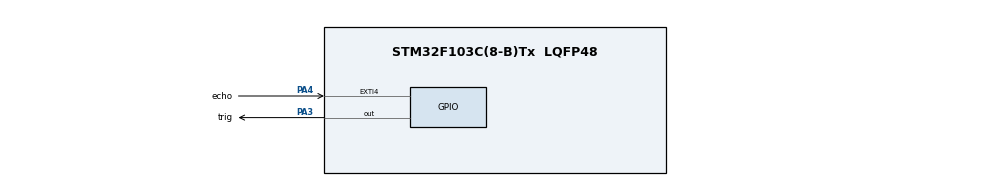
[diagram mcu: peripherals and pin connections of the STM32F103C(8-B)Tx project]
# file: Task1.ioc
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Mcu.Family=STM32F1
Mcu.Name=STM32F103C(8-B)Tx
Mcu.Package=LQFP48
NVIC.EXTI4_IRQn=true\:0\:0\:false\:false\:true\:true\:true\:true
NVIC.PriorityGroup=NVIC_PRIORITYGROUP_4
PA3.GPIO_Label=trig
PA3.Signal=GPIO_Output
PA4.GPIO_Label=echo
PA4.GPIO_ModeDefaultEXTI=GPIO_MODE_IT_RISING_FALLING
PA4.Signal=GPXTI4
ProjectManager.HeapSize=0x200
ProjectManager.StackSize=0x400
ProjectManager.TargetToolchain=STM32CubeIDE
RCC.APB1Freq_Value=8000000
RCC.APB2Freq_Value=8000000
VP_SYS_VS_ND.Mode=No_Debug
VP_TIM1_VS_ClockSourceINT.Mode=Internal
board=custom

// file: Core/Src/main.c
/* USER CODE BEGIN Header */
/**
  ******************************************************************************
  * @file           : main.c
  * @brief          : Main program body
  ******************************************************************************
  * @attention
  *
  * Copyright (c) 2026 STMicroelectronics.
  * All rights reserved.
  *
  * This software is licensed under terms that can be found in the LICENSE file
  * in the root directory of this software component.
  * If no LICENSE file comes with this software, it is provided AS-IS.
  *
  ******************************************************************************
  */
/* USER CODE END Header */
#include "main.h"

TIM_HandleTypeDef htim1;

void SystemClock_Config(void);
static void MX_GPIO_Init(void);
static void MX_TIM1_Init(void);
/* USER CODE BEGIN PFP */
void delay_us(uint16_t us);
/* USER CODE END PFP */

int main(void)
{

  /* MCU Configuration--------------------------------------------------------*/

  /* Reset of all peripherals, Initializes the Flash interface and the Systick. */
  HAL_Init();

  /* Configure the system clock */
  SystemClock_Config();

  /* Initialize all configured peripherals */
  MX_GPIO_Init();
  MX_TIM1_Init();
  /* USER CODE BEGIN 2 */
  HAL_TIM_Base_Start(&htim1);
  LCD_8 l = {
 		  .EN  = { .port = GPIOA, .pin = GPIO_PIN_0 },
 		  .RS  = { .port = GPIOA, .pin = GPIO_PIN_1 },
 		  .RW  = { .port = GPIOA, .pin = GPIO_PIN_2 },
 		  .DB7 = { .port = GPIOB, .pin = GPIO_PIN_7 },
 		  .DB6 = { .port = GPIOB, .pin = GPIO_PIN_6 },
 		  .DB5 = { .port = GPIOB, .pin = GPIO_PIN_5 },
 		  .DB4 = { .port = GPIOB, .pin = GPIO_PIN_4 },
 		  .DB3 = { .port = GPIOB, .pin = GPIO_PIN_3 },
 		  .DB2 = { .port = GPIOB, .pin = GPIO_PIN_2 },
 		  .DB1 = { .port = GPIOB, .pin = GPIO_PIN_1 },
 		  .DB0 = { .port = GPIOB, .pin = GPIO_PIN_0 }
   };
   vidLCDInit(l);
   vidLCDScreenClr(l);
   vidLCDSetCursor(l, R2, C1);
   uint8_t str[16] = "start";
   vidLCDWriteStr(l, str);

   US ultra = {
		   .trig = {
			   .port = GPIOA,
			   .pin = GPIO_PIN_3,
		   },
		   .echo = {
			   .port = GPIOA,
			   .pin = GPIO_PIN_4,

		   },
		   .mode = CM
   };
   uint16_t distance = 5;
   US_read(ultra, &distance);
  /* USER CODE END 2 */

  /* Infinite loop */
  /* USER CODE BEGIN WHILE */
  while (1)
  {

	   US_read(ultra, &distance);
	  sprintf(str, "dist:%d",distance);
	   vidLCDScreenClr(l);
	   vidLCDSetCursor(l, R1, C1);
	   vidLCDWriteStr(l, str);
	  HAL_Delay(100);
    /* USER CODE END WHILE */

  }
}

void SystemClock_Config(void)
{
  RCC_OscInitTypeDef RCC_OscInitStruct = {0};
  RCC_ClkInitTypeDef RCC_ClkInitStruct = {0};

  /** Initializes the RCC Oscillators according to the specified parameters
  * in the RCC_OscInitTypeDef structure.
  */
  RCC_OscInitStruct.OscillatorType = RCC_OSCILLATORTYPE_HSI;
  RCC_OscInitStruct.HSIState = RCC_HSI_ON;
  RCC_OscInitStruct.HSICalibrationValue = RCC_HSICALIBRATION_DEFAULT;
  RCC_OscInitStruct.PLL.PLLState = RCC_PLL_NONE;
  if (HAL_RCC_OscConfig(&RCC_OscInitStruct) != HAL_OK)
  {
    Error_Handler();
  }

  /** Initializes the CPU, AHB and APB buses clocks
  */
  RCC_ClkInitStruct.ClockType = RCC_CLOCKTYPE_HCLK|RCC_CLOCKTYPE_SYSCLK
                              |RCC_CLOCKTYPE_PCLK1|RCC_CLOCKTYPE_PCLK2;
  RCC_ClkInitStruct.SYSCLKSource = RCC_SYSCLKSOURCE_HSI;
  RCC_ClkInitStruct.AHBCLKDivider = RCC_SYSCLK_DIV1;
  RCC_ClkInitStruct.APB1CLKDivider = RCC_HCLK_DIV1;
  RCC_ClkInitStruct.APB2CLKDivider = RCC_HCLK_DIV1;

  if (HAL_RCC_ClockConfig(&RCC_ClkInitStruct, FLASH_LATENCY_0) != HAL_OK)
  {
    Error_Handler();
  }
}

static void MX_TIM1_Init(void)
{

  TIM_ClockConfigTypeDef sClockSourceConfig = {0};
  TIM_MasterConfigTypeDef sMasterConfig = {0};

  htim1.Instance = TIM1;
  htim1.Init.Prescaler = 0;
  htim1.Init.CounterMode = TIM_COUNTERMODE_UP;
  htim1.Init.Period = 65535;
  htim1.Init.ClockDivision = TIM_CLOCKDIVISION_DIV1;
  htim1.Init.RepetitionCounter = 0;
  htim1.Init.AutoReloadPreload = TIM_AUTORELOAD_PRELOAD_DISABLE;
  if (HAL_TIM_Base_Init(&htim1) != HAL_OK)
  {
    Error_Handler();
  }
  sClockSourceConfig.ClockSource = TIM_CLOCKSOURCE_INTERNAL;
  if (HAL_TIM_ConfigClockSource(&htim1, &sClockSourceConfig) != HAL_OK)
  {
    Error_Handler();
  }
  sMasterConfig.MasterOutputTrigger = TIM_TRGO_RESET;
  sMasterConfig.MasterSlaveMode = TIM_MASTERSLAVEMODE_DISABLE;
  if (HAL_TIMEx_MasterConfigSynchronization(&htim1, &sMasterConfig) != HAL_OK)
  {
    Error_Handler();
  }

}

static void MX_GPIO_Init(void)
{
  GPIO_InitTypeDef GPIO_InitStruct = {0};

  /* GPIO Ports Clock Enable */
  __HAL_RCC_GPIOA_CLK_ENABLE();

  /*Configure GPIO pin Output Level */
  HAL_GPIO_WritePin(trig_GPIO_Port, trig_Pin, GPIO_PIN_RESET);

  /*Configure GPIO pin : trig_Pin */
  GPIO_InitStruct.Pin = trig_Pin;
  GPIO_InitStruct.Mode = GPIO_MODE_OUTPUT_PP;
  GPIO_InitStruct.Pull = GPIO_NOPULL;
  GPIO_InitStruct.Speed = GPIO_SPEED_FREQ_LOW;
  HAL_GPIO_Init(trig_GPIO_Port, &GPIO_InitStruct);

  /*Configure GPIO pin : echo_Pin */
  GPIO_InitStruct.Pin = echo_Pin;
  GPIO_InitStruct.Mode = GPIO_MODE_IT_RISING_FALLING;
  GPIO_InitStruct.Pull = GPIO_NOPULL;
  HAL_GPIO_Init(echo_GPIO_Port, &GPIO_InitStruct);

  /* EXTI interrupt init*/
  HAL_NVIC_SetPriority(EXTI4_IRQn, 0, 0);
  HAL_NVIC_EnableIRQ(EXTI4_IRQn);

}

/* USER CODE BEGIN 4 */
void delay_us(uint16_t us)
{
//	what are the enhancements we can do here??
	const uint8_t usTicks = 8;
	uint16_t start = htim1.Instance->CNT;
	while((uint16_t)(htim1.Instance->CNT - start) < us*usTicks);
}
/* USER CODE END 4 */

void Error_Handler(void)
{
  __disable_irq();
  while (1)
  {
  }
}
